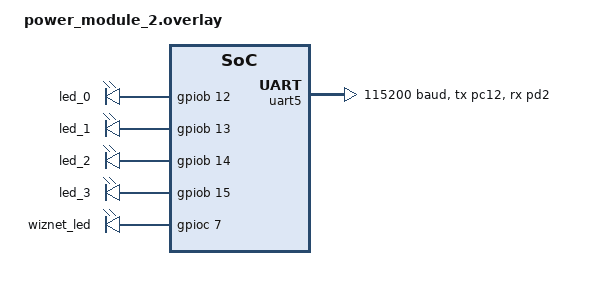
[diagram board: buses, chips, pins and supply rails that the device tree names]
/ {
    aliases {
//        debug-uart = &uart;
        led0 = &led_0;
        led1 = &led_1;
        led2 = &led_2;
        led3 = &led_3;
        ledwiz = &wiznet_led;
        uartdbg = &uart5;
    };

    leds: leds {
		compatible = "gpio-leds";
        led_0: led_0 {
            gpios = <&gpiob 12 GPIO_ACTIVE_HIGH>;
        };

        led_1: led_1 {
            gpios = <&gpiob 13 GPIO_ACTIVE_HIGH>;
        };

        led_2: led_2 {
            gpios = <&gpiob 14 GPIO_ACTIVE_HIGH>;
        };

        led_3: led_3 {
            gpios = <&gpiob 15 GPIO_ACTIVE_HIGH>;
        };

        wiznet_led: wiznet_led {
            gpios = <&gpioc 7 GPIO_ACTIVE_HIGH>;
        };
	};
};


/ {
    chosen {
        zephyr,console = &uart5;
		zephyr,shell-uart = &uart5;
    };
};

/ {
    soc {
        uart5: serial@40005000 {
            pinctrl-0 = <&uart5_tx_pc12 &uart5_rx_pd2>;
            pinctrl-names = "default";
            current-speed = <115200>;
            status = "okay";
        };
    };
};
